# MIMXRT1062 register map
Vendor: nxp.com; File version: 1.0
CPU: CM7 r0p1, little endian, MPU, FPU, VTOR, 4 interrupt priority bits
Registers are 32-bit, read-write, reset 0x0 unless marked. A register's access mark holds for its fields unless they carry their own. Offsets are from the block's base; [hi:lo] are bit positions; 'fields as' and 'values as' point back to an identical list.

## PXP — PXP v2.0 Register Reference Index
Base 0x402B4000; register names take the prefix PXP_
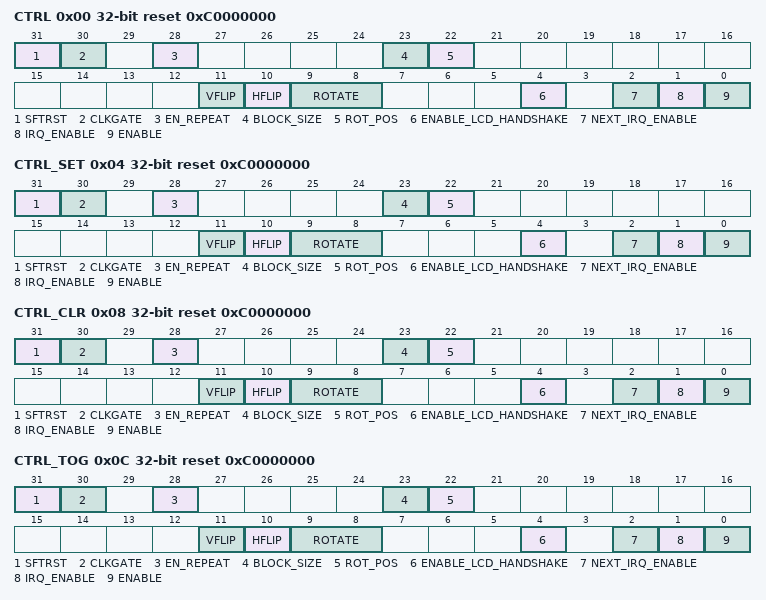
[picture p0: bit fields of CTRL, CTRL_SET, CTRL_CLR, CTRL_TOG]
0x00 CTRL reset 0xC0000000 — Control Register 0
  [31] SFTRST — Set this bit to zero to enable normal PXP operation
  [30] CLKGATE — This bit must be set to zero for normal operation
  [28] EN_REPEAT — Enable the PXP to run continuously
  [23] BLOCK_SIZE — Select the block size to process.
    0=8X8 (Process 8x8 pixel blocks.); 1=16X16 (Process 16x16 pixel blocks.)
  [22] ROT_POS — This bit controls where rotation will occur in the PXP datapath
  [11] VFLIP — Indicates that the output buffer should be flipped vertically (effect applied before rotation).
  [10] HFLIP — Indicates that the output buffer should be flipped horizontally (effect applied before rotation).
  [9:8] ROTATE — Indicates the clockwise rotation to be applied at the output buffer
    0=ROT_0; 1=ROT_90; 2=ROT_180; 3=ROT_270
  [4] ENABLE_LCD_HANDSHAKE — Enable handshake with LCD controller
  [2] NEXT_IRQ_ENABLE — Next command interrupt enable
  [1] IRQ_ENABLE — Interrupt enable
  [0] ENABLE — Enables PXP operation with specified parameters
0x04 CTRL_SET reset 0xC0000000 — Control Register 0
  fields as CTRL
0x08 CTRL_CLR reset 0xC0000000 — Control Register 0
  fields as CTRL
0x0C CTRL_TOG reset 0xC0000000 — Control Register 0
  fields as CTRL
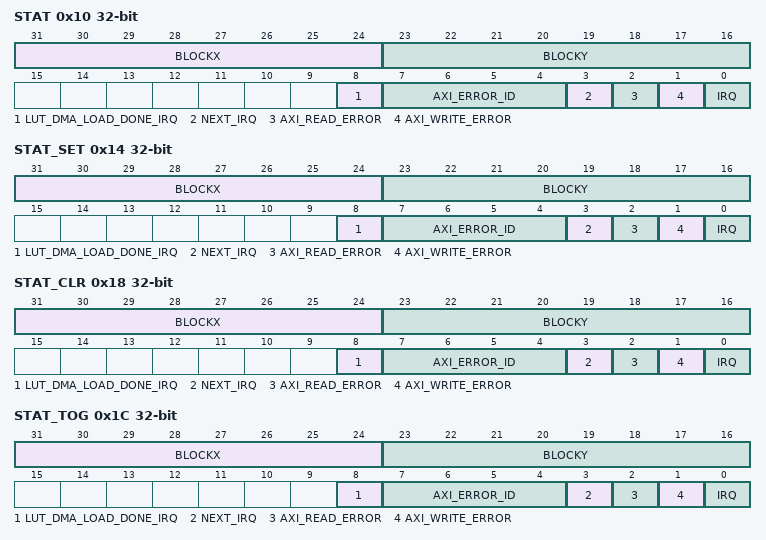
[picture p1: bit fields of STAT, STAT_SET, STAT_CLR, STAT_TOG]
0x10 STAT — Status Register
  [31:24] BLOCKX ro — Indicates the X coordinate of the block currently being rendered.
  [23:16] BLOCKY ro — Indicates the X coordinate of the block currently being rendered.
  [8] LUT_DMA_LOAD_DONE_IRQ — Indicates that the LUT DMA transfer has completed.
  [7:4] AXI_ERROR_ID ro — Indicates the AXI ID of the failing bus operation.
  [3] NEXT_IRQ — Indicates that a command issued with the "Next Command" functionality has been issued and that a new command may be initiated with a write to the PXP_NEXT register
  [2] AXI_READ_ERROR — Indicates PXP encountered an AXI read error and processing has been terminated.
  [1] AXI_WRITE_ERROR — Indicates PXP encountered an AXI write error and processing has been terminated.
  [0] IRQ — Indicates current PXP interrupt status
0x14 STAT_SET — Status Register
  fields as STAT
0x18 STAT_CLR — Status Register
  fields as STAT
0x1C STAT_TOG — Status Register
  fields as STAT
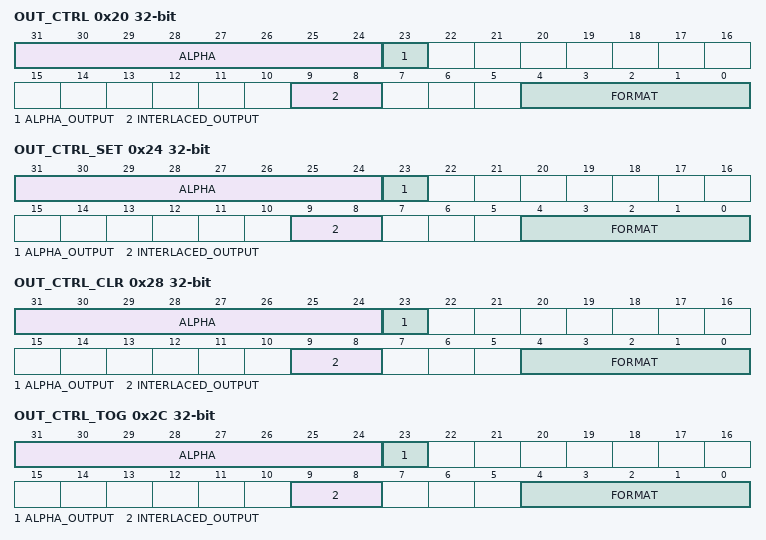
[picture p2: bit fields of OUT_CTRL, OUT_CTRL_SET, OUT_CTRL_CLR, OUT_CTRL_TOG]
0x20 OUT_CTRL — Output Buffer Control Register
  [31:24] ALPHA — When generating an output buffer with an alpha component, the value in this field will be used when enabled to override the alpha passed through the pixel data pipeline
  [23] ALPHA_OUTPUT — Indicates that alpha component in output buffer pixels should be overwritten by PXP_OUT_CTRL[ALPHA]
  [9:8] INTERLACED_OUTPUT — Determines how the PXP writes it's output data
    0=PROGRESSIVE (All data written in progressive format to the OUTBUF Pointer.); 1=FIELD0 (Interlaced output: only data for field 0 is written to the OUTBUF Pointer.); 2=FIELD1 (Interlaced output: only data for field 1 is written to the OUTBUF2 Pointer.); 3=INTERLACED (Interlaced output: data for field 0 is written to OUTBUF and data for field 1 is written to OUTBUF2.)
  [4:0] FORMAT — Output framebuffer format
    0=ARGB8888 (32-bit pixels); 4=RGB888 (32-bit pixels (unpacked 24-bit pixel in 32 bit DWORD.)); 5=RGB888P (24-bit pixels (packed 24-bit format)); 8=ARGB1555 (16-bit pixels); 9=ARGB4444 (16-bit pixels); 12=RGB555 (16-bit pixels); 13=RGB444 (16-bit pixels); 14=RGB565 (16-bit pixels); 16=YUV1P444 (32-bit pixels (1-plane XYUV unpacked)); 18=UYVY1P422 (16-bit pixels (1-plane U0,Y0,V0,Y1 interleaved bytes)); 19=VYUY1P422 (16-bit pixels (1-plane V0,Y0,U0,Y1 interleaved bytes)); 20=Y8 (8-bit monochrome pixels (1-plane Y luma output)); 21=Y4 (4-bit monochrome pixels (1-plane Y luma, 4 bit truncation)); 24=YUV2P422 (16-bit pixels (2-plane UV interleaved bytes)); 25=YUV2P420 (16-bit pixels (2-plane UV)); 26=YVU2P422 (16-bit pixels (2-plane VU interleaved bytes)); 27=YVU2P420 (16-bit pixels (2-plane VU))
0x24 OUT_CTRL_SET — Output Buffer Control Register
  fields as OUT_CTRL
0x28 OUT_CTRL_CLR — Output Buffer Control Register
  fields as OUT_CTRL
0x2C OUT_CTRL_TOG — Output Buffer Control Register
  fields as OUT_CTRL
0x30 OUT_BUF — Output Frame Buffer Pointer
  [31:0] ADDR — Current address pointer for the output frame buffer
0x40 OUT_BUF2 — Output Frame Buffer Pointer #2
  [31:0] ADDR — Current address pointer for the output frame buffer
0x50 OUT_PITCH — Output Buffer Pitch
  [15:0] PITCH — Indicates the number of bytes in memory between two vertically adjacent pixels.
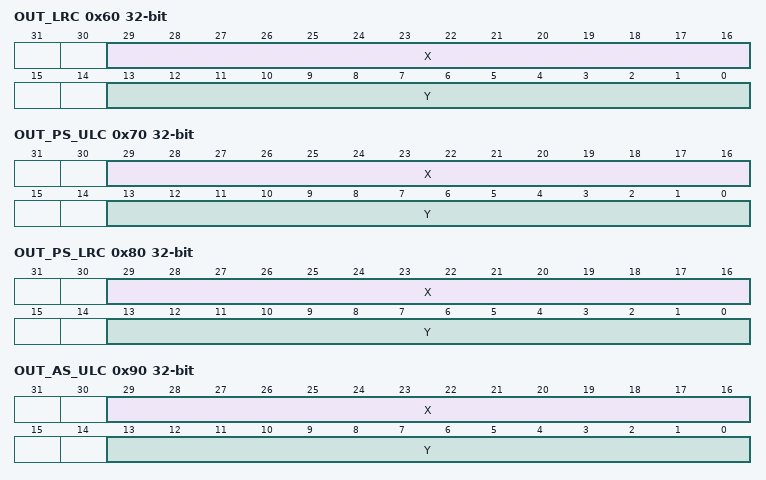
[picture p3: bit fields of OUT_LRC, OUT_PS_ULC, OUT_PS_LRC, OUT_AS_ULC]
0x60 OUT_LRC — Output Surface Lower Right Coordinate
  [29:16] X — Indicates number of horizontal PIXELS in the output surface (non-rotated)
  [13:0] Y — Indicates the number of vertical PIXELS in the output surface (non-rotated)
0x70 OUT_PS_ULC — Processed Surface Upper Left Coordinate
  [29:16] X — This field indicates the upper left X-coordinate (in pixels) of the processed surface (PS) in the output buffer
  [13:0] Y — This field indicates the upper left Y-coordinate (in pixels) of the processed surface in the output buffer
0x80 OUT_PS_LRC — Processed Surface Lower Right Coordinate
  [29:16] X — This field indicates the lower right X-coordinate (in pixels) of the processed surface (PS) in the output frame buffer
  [13:0] Y — This field indicates the lower right Y-coordinate (in pixels) of the processed surface in the output frame buffer
0x90 OUT_AS_ULC — Alpha Surface Upper Left Coordinate
  [29:16] X — This field indicates the upper left X-coordinate (in pixels) of the alpha surface (AS) in the output frame buffer
  [13:0] Y — This field indicates the upper left Y-coordinate (in pixels) of the alpha surface in the output frame buffer
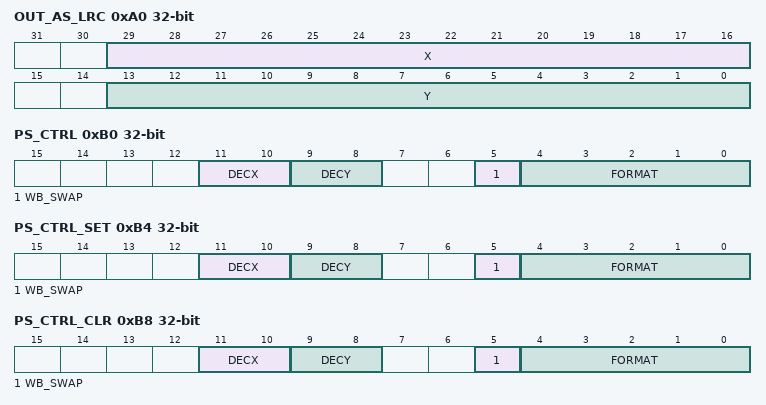
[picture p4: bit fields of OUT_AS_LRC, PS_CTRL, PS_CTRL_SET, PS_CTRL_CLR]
0xA0 OUT_AS_LRC — Alpha Surface Lower Right Coordinate
  [29:16] X — This field indicates the lower right X-coordinate (in pixels) of the alpha surface (AS) in the output frame buffer
  [13:0] Y — This field indicates the lower right Y-coordinate (in pixels) of the alpha surface in the output frame buffer
0xB0 PS_CTRL — Processed Surface (PS) Control Register
  [11:10] DECX — Horizontal pre decimation filter control.
    0=DISABLE (Disable pre-decimation filter.); 1=Decimate PS by 2; 2=Decimate PS by 4; 3=Decimate PS by 8
  [9:8] DECY — Verticle pre decimation filter control.
    values as DECX
  [5] WB_SWAP — Swap bytes in words. For each 16 bit word, the two bytes will be swapped.
  [4:0] FORMAT — PS buffer format. To select between YUV and YCbCr formats, see bit 31 of the CSC1_COEF0 register.
    4=RGB888 (32-bit pixels (unpacked 24-bit format)); 12=RGB555 (16-bit pixels); 13=RGB444 (16-bit pixels); 14=RGB565 (16-bit pixels); 16=YUV1P444 (32-bit pixels (1-plane XYUV unpacked)); 18=UYVY1P422 (16-bit pixels (1-plane U0,Y0,V0,Y1 interleaved bytes)); 19=VYUY1P422 (16-bit pixels (1-plane V0,Y0,U0,Y1 interleaved bytes)); 20=Y8 (8-bit monochrome pixels (1-plane Y luma output)); 21=Y4 (4-bit monochrome pixels (1-plane Y luma, 4 bit truncation)); 24=YUV2P422 (16-bit pixels (2-plane UV interleaved bytes)); 25=YUV2P420 (16-bit pixels (2-plane UV)); 26=YVU2P422 (16-bit pixels (2-plane VU interleaved bytes)); 27=YVU2P420 (16-bit pixels (2-plane VU)); 30=YUV422 (16-bit pixels (3-plane format)); 31=YUV420 (16-bit pixels (3-plane format))
0xB4 PS_CTRL_SET — Processed Surface (PS) Control Register
  fields as PS_CTRL
0xB8 PS_CTRL_CLR — Processed Surface (PS) Control Register
  fields as PS_CTRL
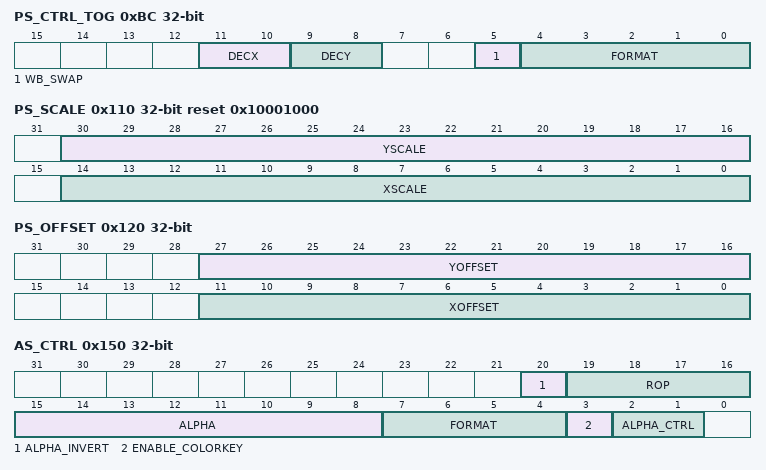
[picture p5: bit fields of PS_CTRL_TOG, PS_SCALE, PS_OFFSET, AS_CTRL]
0xBC PS_CTRL_TOG — Processed Surface (PS) Control Register
  fields as PS_CTRL
0xC0 PS_BUF — PS Input Buffer Address
  [31:0] ADDR — Address pointer for the PS RGB or Y (luma) input buffer.
0xD0 PS_UBUF — PS U/Cb or 2 Plane UV Input Buffer Address
  [31:0] ADDR — Address pointer for the PS U/Cb or 2 plane UV Chroma input buffer.
0xE0 PS_VBUF — PS V/Cr Input Buffer Address
  [31:0] ADDR — Address pointer for the PS V/Cr Chroma input buffer.
0xF0 PS_PITCH — Processed Surface Pitch
  fields as OUT_PITCH
0x100 PS_BACKGROUND — PS Background Color
  [23:0] COLOR — Background color (in 24bpp format) for any pixels not within the buffer range specified by the PS ULC/LRC
0x110 PS_SCALE reset 0x10001000 — PS Scale Factor Register
  [30:16] YSCALE — This is a two bit integer and 12 bit fractional representation (##
  [14:0] XSCALE — This is a two bit integer and 12 bit fractional representation (##
0x120 PS_OFFSET — PS Scale Offset Register
  [27:16] YOFFSET — This is a 12 bit fractional representation (0
  [11:0] XOFFSET — This is a 12 bit fractional representation (0
0x130 PS_CLRKEYLOW reset 0xFFFFFF — PS Color Key Low
  [23:0] PIXEL — Low range of color key applied to PS buffer
0x140 PS_CLRKEYHIGH — PS Color Key High
  [23:0] PIXEL — High range of color key applied to PS buffer
0x150 AS_CTRL — Alpha Surface Control
  [20] ALPHA_INVERT — Setting this bit to logic 0 will not alter the alpha value
  [19:16] ROP — Indicates a raster operation to perform when enabled
    0=MASKAS (AS AND PS); 1=MASKNOTAS (nAS AND PS); 2=MASKASNOT (AS AND nPS); 3=MERGEAS (AS OR PS); 4=MERGENOTAS (nAS OR PS); 5=MERGEASNOT (AS OR nPS); 6=NOTCOPYAS (nAS); 7=NOT (nPS); 8=NOTMASKAS (AS NAND PS); 9=NOTMERGEAS (AS NOR PS); 10=XORAS (AS XOR PS); 11=NOTXORAS (AS XNOR PS)
  [15:8] ALPHA — Alpha modifier used when the ALPHA_MULTIPLY or ALPHA_OVERRIDE values are programmed in PXP_AS_CTRL[ALPHA_CTRL]
  [7:4] FORMAT — Indicates the input buffer format for AS.
    0=ARGB8888 (32-bit pixels with alpha); 4=RGB888 (32-bit pixels without alpha (unpacked 24-bit format)); 8=ARGB1555 (16-bit pixels with alpha); 9=ARGB4444 (16-bit pixels with alpha); 12=RGB555 (16-bit pixels without alpha); 13=RGB444 (16-bit pixels without alpha); 14=RGB565 (16-bit pixels without alpha)
  [3] ENABLE_COLORKEY — Indicates that colorkey functionality is enabled for this alpha surface
  [2:1] ALPHA_CTRL — Determines how the alpha value is constructed for this alpha surface
    0=Embedded (Indicates that the AS pixel alpha value will be used to blend the AS with PS. The ALPHA field is ignored.); 1=Override (Indicates that the value in the ALPHA field should be used instead of the alpha values present in the input pixels.); 2=Multiply (Indicates that the value in the ALPHA field should be used to scale all pixel alpha values. Each pixel alpha is multiplied by the value in the ALPHA field.); 3=ROPs (Enable ROPs. The ROP field indicates an operation to be performed on the alpha surface and PS pixels.)
0x160 AS_BUF — Alpha Surface Buffer Pointer
  [31:0] ADDR — Address pointer for the alpha surface 0 buffer.
0x170 AS_PITCH — Alpha Surface Pitch
  fields as OUT_PITCH
0x180 AS_CLRKEYLOW reset 0xFFFFFF — Overlay Color Key Low
  [23:0] PIXEL — Low range of RGB color key applied to AS buffer. Each overlay has an independent colorkey enable.
0x190 AS_CLRKEYHIGH — Overlay Color Key High
  [23:0] PIXEL — High range of RGB color key applied to AS buffer. Each overlay has an independent colorkey enable.
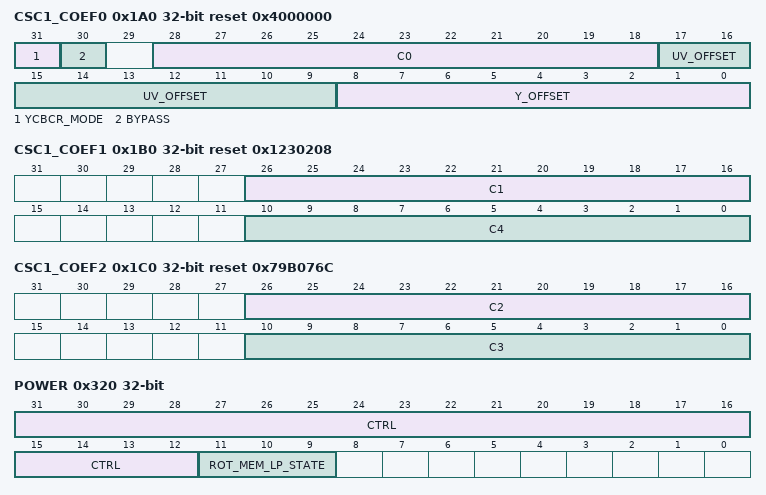
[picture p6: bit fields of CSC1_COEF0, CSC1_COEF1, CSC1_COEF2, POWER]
0x1A0 CSC1_COEF0 reset 0x4000000 — Color Space Conversion Coefficient Register 0
  [31] YCBCR_MODE — Set to 1 when performing YCbCr conversion to RGB
  [30] BYPASS — Bypass the CSC unit in the scaling engine
  [28:18] C0 — Two's compliment Y multiplier coefficient. YUV=0x100 (1.000) YCbCr=0x12A (1.164)
  [17:9] UV_OFFSET — Two's compliment phase offset implicit for CbCr data
  [8:0] Y_OFFSET — Two's compliment amplitude offset implicit in the Y data
0x1B0 CSC1_COEF1 reset 0x1230208 — Color Space Conversion Coefficient Register 1
  [26:16] C1 — Two's compliment Red V/Cr multiplier coefficient. YUV=0x123 (1.140) YCbCr=0x198 (1.596)
  [10:0] C4 — Two's compliment Blue U/Cb multiplier coefficient. YUV=0x208 (2.032) YCbCr=0x204 (2.017)
0x1C0 CSC1_COEF2 reset 0x79B076C — Color Space Conversion Coefficient Register 2
  [26:16] C2 — Two's complement Green V/Cr multiplier coefficient. YUV=0x76B (-0.581) YCbCr=0x730 (-0.813)
  [10:0] C3 — Two's complement Green U/Cb multiplier coefficient. YUV=0x79C (-0.394) YCbCr=0x79C (-0.392)
0x320 POWER — PXP Power Control Register
  [31:12] CTRL — Power control for the PXP.
  [11:9] ROT_MEM_LP_STATE — Select the low power state of the ROT memory.
    0=NONE (Memory is not in low power state.); 1=LS (Light Sleep Mode. Low leakage mode, maintain memory contents.); 2=DS (Deep Sleep Mode. Low leakage mode, maintain memory contents.); 4=SD (Shut Down Mode. Shut Down periphery and core, no memory retention.)
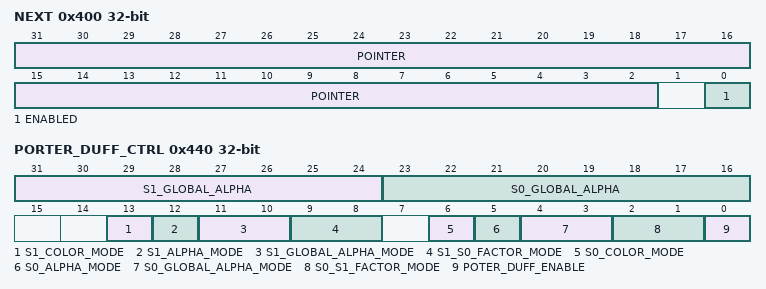
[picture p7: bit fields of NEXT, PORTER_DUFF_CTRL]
0x400 NEXT — Next Frame Pointer
  [31:2] POINTER — A pointer to a data structure containing register values to be used when processing the next frame
  [0] ENABLED ro — Indicates that the "next frame" functionality has been enabled
0x440 PORTER_DUFF_CTRL — PXP Alpha Engine A Control Register.
  [31:24] S1_GLOBAL_ALPHA
  [23:16] S0_GLOBAL_ALPHA
  [13] S1_COLOR_MODE
  [12] S1_ALPHA_MODE
  [11:10] S1_GLOBAL_ALPHA_MODE
  [9:8] S1_S0_FACTOR_MODE — s1 to s0 factor mode
  [6] S0_COLOR_MODE
  [5] S0_ALPHA_MODE
  [4:3] S0_GLOBAL_ALPHA_MODE
  [2:1] S0_S1_FACTOR_MODE — s0 to s1 factor mode
  [0] POTER_DUFF_ENABLE
